AUTOSAR XML (schema 4-0-3)
standard types defined: Boolean, UInt16
package /AUTOSAR_Platform/DataConstrs
  range DC_Boolean: raw 0..1
  range DC_UInt16: raw 0..65535
package /PATAC/MSM/ComponentTypes
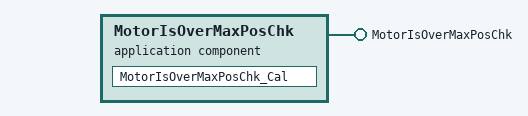
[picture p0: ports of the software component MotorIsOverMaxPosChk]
  application sw component type MotorIsOverMaxPosChk
    provide port MotorIsOverMaxPosChk: server-com-spec{operation=Cal, queue-length=1}, provided-interface=MotorIsOverMaxPosChk
    behavior MotorIsOverMaxPosChk_InternalBehavior
      operation invoked event OIT_MotorIsOverMaxPosChk_Cal_MotorIsOverMaxPosChk_Cal: start-on-event=MotorIsOverMaxPosChk_Cal, operation=MotorIsOverMaxPosChk.Cal
      runnable MotorIsOverMaxPosChk_Cal
  swc implementation MotorIsOverMaxPosChk_Implementation: behavior=MotorIsOverMaxPosChk_InternalBehavior
    code-descriptors:
      code Default: artifact-descriptors=autosar-engineering-object={short-label=Default, category=SWSRC}
package /PATAC/MSM/ModeAdjust/DataType
  impl type TrgtPosCalibArray: category=ARRAY, sw-calibration-access=READ-ONLY, type-emitter=RTE  # 0:pos 1:max 2:min
    element Element: array-size=3, array-size-semantics=FIXED-SIZE, implementation-data-type=UInt16, invalid-value=0
package /PATAC/MSM/ModeAdjust/PortInterface
  client server interface MotorIsOverMaxPosChk
    operation Cal
      5 x arg, all with server-argument-impl-policy=USE-ARGUMENT-TYPE:
        PosV: type=Boolean, direction=IN
        Pos: type=UInt16, direction=IN
        TrgtPosCalib: type=TrgtPosCalibArray, direction=IN
        Delta: type=UInt16, direction=IN
        IsOverMaxTrgtPos: type=Boolean, direction=OUT
